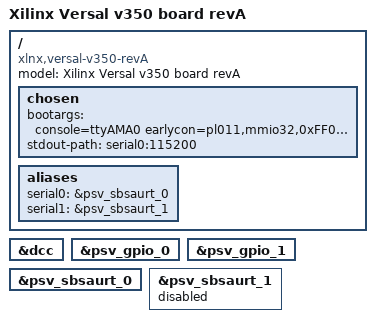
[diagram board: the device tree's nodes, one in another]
// SPDX-License-Identifier: GPL-2.0
/*
 * dts file for Xilinx Versal v350 revA
 *
 * (C) Copyright 2019, Xilinx, Inc.
 *
 * Michal Simek <michal.simek@xilinx.com>
 */


/ {
	compatible = "xlnx,versal-v350-revA", "xlnx,versal";
	model = "Xilinx Versal v350 board revA";

	chosen {
		bootargs = "console=ttyAMA0 earlycon=pl011,mmio32,0xFF010000,115200n8 clk_ignore_unused";
		stdout-path = "serial0:115200";
	};

	aliases {
		serial0 = &psv_sbsaurt_0;
		serial1 = &psv_sbsaurt_1;
	};
};

&dcc {
	status = "okay";
};

&psv_gpio_0 {
	status = "okay";
};

&psv_gpio_1 {
	status = "okay";
};

&psv_sbsaurt_0 {
	status = "okay";
};

&psv_sbsaurt_1 {
	status = "disabled"; /* communication with MSP432 */
};
